# CortexM33 register map
Extracted from https://github.com/rp-rs/rp235x-pac/blob/main/svd/RP2350.svd.patched
CPU: CM33 r1p0, little endian, MPU, FPU, DSP, VTOR, 4 interrupt priority bits, 52 interrupts, 8 SAU regions
Registers are read-write, reset 0x0 unless marked. A register's access mark holds for its fields unless they carry their own. Offsets are from the block's base; lines under a group give offsets from that group; [hi:lo] are bit positions; {n}, {i} and the like mark numbered series; 'fields as' and 'values as' point back to an identical list; <NAME> marks a mode.

## Memory map
0xE0000000 PPB size 0x43000 — TEAL registers accessible through the debug interface
0xE0080000 EPPB size 0xC — Cortex-M33 EPPB vendor register block for RP2350

## EPPB — Cortex-M33 EPPB vendor register block for RP2350
Base 0xE0080000
0x00 NMI_MASK0 — NMI mask for IRQs 0 through 31. This register is core-local, and is reset by a processor warm reset.
  [31:0] NMI_MASK0
0x04 NMI_MASK1 — NMI mask for IRQs 0 though 51. This register is core-local, and is reset by a processor warm reset.
  [19:0] NMI_MASK1
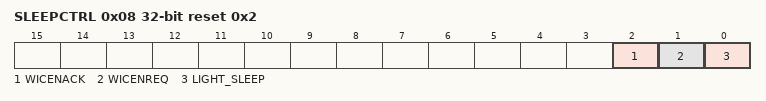
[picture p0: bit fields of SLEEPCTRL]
0x08 SLEEPCTRL access per field reset 0x2 — Nonstandard sleep control register
  [2] WICENACK ro — Status signal from the processor's interrupt controller. Changes to WICENREQ are eventually reflected in WICENACK.
  [1] WICENREQ rw — Request that the next processor deep sleep is a WIC sleep. After setting this bit, before sleeping, poll WICENACK to ensure the processor interrupt controller has acknowledged the change.
  [0] LIGHT_SLEEP rw — By default, any processor sleep will deassert the system-level clock request. Reenabling the clocks incurs 5 cycles of additional latency on wakeup. Setting LIGHT_SLEEP to 1 keeps the clock request asserted during a normal sleep (Arm SCR.SLEEPDEEP = 0), for faster wakeup. Processor deep sleep (Arm SCR.SLEEPDEEP = 1) is not affected, and will always deassert the system-level clock request.

## PPB (part 1 of 2) — TEAL registers accessible through the debug interface
Base 0xE0000000
{0x0+4i} ITM_STIM{i} (i=0..31) — Provides the interface for generating Instrumentation packets
  [31:0] STIMULUS — Data to write to the Stimulus Port FIFO, for forwarding as an Instrumentation packet. The size of write access determines the type of Instrumentation packet generated.
0xE00 ITM_TER0 — Provide an individual enable bit for each ITM_STIM register
  [31:0] STIMENA — For STIMENA[m] in ITM_TER*n, controls whether ITM_STIM(32*n + m) is enabled
0xE40 ITM_TPR — Controls which stimulus ports can be accessed by unprivileged code
  [3:0] PRIVMASK — Bit mask to enable tracing on ITM stimulus ports
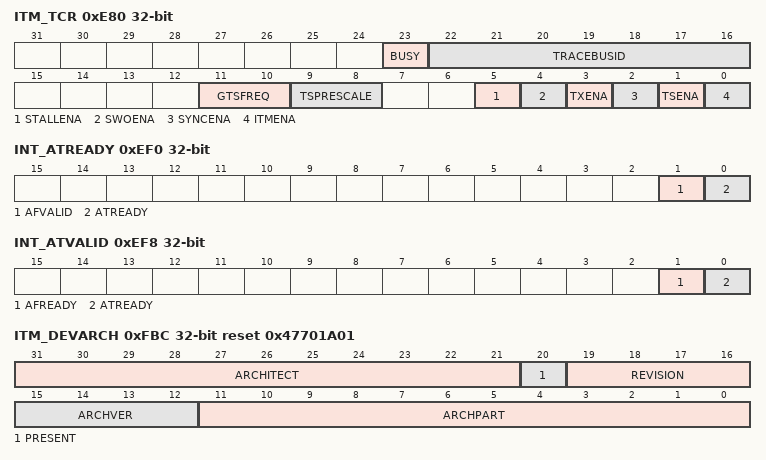
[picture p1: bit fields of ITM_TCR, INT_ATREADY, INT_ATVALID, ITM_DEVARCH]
0xE80 ITM_TCR access per field — Configures and controls transfers through the ITM interface
  [23] BUSY ro — Indicates whether the ITM is currently processing events
  [22:16] TRACEBUSID rw — Identifier for multi-source trace stream formatting. If multi-source trace is in use, the debugger must write a unique non-zero trace ID value to this field
  [11:10] GTSFREQ rw — Defines how often the ITM generates a global timestamp, based on the global timestamp clock frequency, or disables generation of global timestamps
  [9:8] TSPRESCALE rw — Local timestamp prescaler, used with the trace packet reference clock
  [5] STALLENA rw — Stall the PE to guarantee delivery of Data Trace packets.
  [4] SWOENA rw — Enables asynchronous clocking of the timestamp counter
  [3] TXENA rw — Enables forwarding of hardware event packet from the DWT unit to the ITM for output to the TPIU
  [2] SYNCENA rw — Enables Synchronization packet transmission for a synchronous TPIU
  [1] TSENA rw — Enables Local timestamp generation
  [0] ITMENA rw — Enables the ITM
0xEF0 INT_ATREADY ro — Integration Mode: Read ATB Ready
  [1] AFVALID — A read of this bit returns the value of AFVALID
  [0] ATREADY — A read of this bit returns the value of ATREADY
0xEF8 INT_ATVALID — Integration Mode: Write ATB Valid
  [1] AFREADY — A write to this bit gives the value of AFREADY
  [0] ATREADY — A write to this bit gives the value of ATVALID
0xF00 ITM_ITCTRL — Integration Mode Control Register
  [0] IME — Integration mode enable bit - The possible values are: 0 - The trace unit is not in integration mode. 1 - The trace unit is in integration mode. This mode enables: A debug agent to perform topology detection. SoC test software to perform integration testing.
0xFBC ITM_DEVARCH ro reset 0x47701A01 — Provides CoreSight discovery information for the ITM
  [31:21] ARCHITECT — Defines the architect of the component. Bits [31:28] are the JEP106 continuation code (JEP106 bank ID, minus 1) and bits [27:21] are the JEP106 ID code.
  [20] PRESENT — Defines that the DEVARCH register is present
  [19:16] REVISION — Defines the architecture revision of the component
  [15:12] ARCHVER — Defines the architecture version of the component
  [11:0] ARCHPART — Defines the architecture of the component
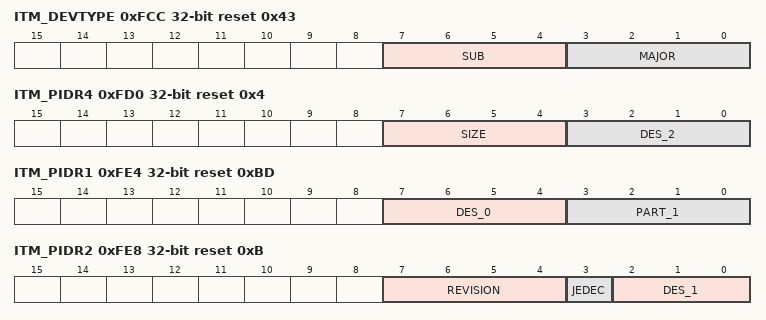
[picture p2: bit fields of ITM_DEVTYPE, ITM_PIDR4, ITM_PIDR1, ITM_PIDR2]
0xFCC ITM_DEVTYPE ro reset 0x43 — Provides CoreSight discovery information for the ITM
  [7:4] SUB — Component sub-type
  [3:0] MAJOR — Component major type
0xFD0 ITM_PIDR4 ro reset 0x4 — Provides CoreSight discovery information for the ITM
  [7:4] SIZE — See CoreSight Architecture Specification
  [3:0] DES_2 — See CoreSight Architecture Specification
{0xFC0+4i} ITM_PIDR{i} (i=5..7) — Provides CoreSight discovery information for the ITM
  [31:0] ITM_PIDR{i}
0xFE0 ITM_PIDR0 ro reset 0x21 — Provides CoreSight discovery information for the ITM
  [7:0] PART_0 — See CoreSight Architecture Specification
0xFE4 ITM_PIDR1 ro reset 0xBD — Provides CoreSight discovery information for the ITM
  [7:4] DES_0 — See CoreSight Architecture Specification
  [3:0] PART_1 — See CoreSight Architecture Specification
0xFE8 ITM_PIDR2 ro reset 0xB — Provides CoreSight discovery information for the ITM
  [7:4] REVISION — See CoreSight Architecture Specification
  [3] JEDEC — See CoreSight Architecture Specification
  [2:0] DES_1 — See CoreSight Architecture Specification
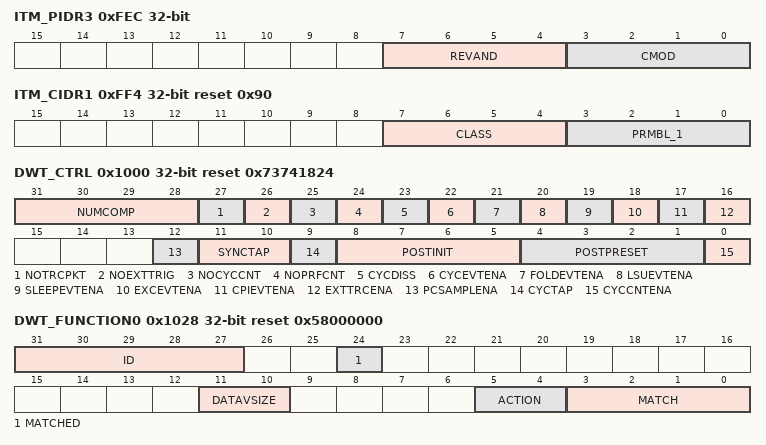
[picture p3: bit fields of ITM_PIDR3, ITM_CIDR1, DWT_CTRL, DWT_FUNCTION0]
0xFEC ITM_PIDR3 ro — Provides CoreSight discovery information for the ITM
  [7:4] REVAND — See CoreSight Architecture Specification
  [3:0] CMOD — See CoreSight Architecture Specification
0xFF0 ITM_CIDR0 ro reset 0xD — Provides CoreSight discovery information for the ITM
  [7:0] PRMBL_0 — See CoreSight Architecture Specification
0xFF4 ITM_CIDR1 ro reset 0x90 — Provides CoreSight discovery information for the ITM
  [7:4] CLASS — See CoreSight Architecture Specification
  [3:0] PRMBL_1 — See CoreSight Architecture Specification
0xFF8 ITM_CIDR2 ro reset 0x5 — Provides CoreSight discovery information for the ITM
  [7:0] PRMBL_2 — See CoreSight Architecture Specification
0xFFC ITM_CIDR3 ro reset 0xB1 — Provides CoreSight discovery information for the ITM
  [7:0] PRMBL_3 — See CoreSight Architecture Specification
0x1000 DWT_CTRL access per field reset 0x73741824 — Provides configuration and status information for the DWT unit, and used to control features of the unit
  [31:28] NUMCOMP ro — Number of DWT comparators implemented
  [27] NOTRCPKT ro — Indicates whether the implementation does not support trace
  [26] NOEXTTRIG ro — Reserved, RAZ
  [25] NOCYCCNT ro — Indicates whether the implementation does not include a cycle counter
  [24] NOPRFCNT ro — Indicates whether the implementation does not include the profiling counters
  [23] CYCDISS rw — Controls whether the cycle counter is disabled in Secure state
  [22] CYCEVTENA rw — Enables Event Counter packet generation on POSTCNT underflow
  [21] FOLDEVTENA rw — Enables DWT_FOLDCNT counter
  [20] LSUEVTENA rw — Enables DWT_LSUCNT counter
  [19] SLEEPEVTENA rw — Enable DWT_SLEEPCNT counter
  [18] EXCEVTENA rw — Enables DWT_EXCCNT counter
  [17] CPIEVTENA rw — Enables DWT_CPICNT counter
  [16] EXTTRCENA rw — Enables generation of Exception Trace packets
  [12] PCSAMPLENA rw — Enables use of POSTCNT counter as a timer for Periodic PC Sample packet generation
  [11:10] SYNCTAP rw — Selects the position of the synchronization packet counter tap on the CYCCNT counter. This determines the Synchronization packet rate
  [9] CYCTAP rw — Selects the position of the POSTCNT tap on the CYCCNT counter
  [8:5] POSTINIT rw — Initial value for the POSTCNT counter
  [4:1] POSTPRESET rw — Reload value for the POSTCNT counter
  [0] CYCCNTENA rw — Enables CYCCNT
0x1004 DWT_CYCCNT — Shows or sets the value of the processor cycle counter, CYCCNT
  [31:0] CYCCNT — Increments one on each processor clock cycle when DWT_CTRL.CYCCNTENA == 1 and DEMCR.TRCENA == 1. On overflow, CYCCNT wraps to zero
0x100C DWT_EXCCNT — Counts the total cycles spent in exception processing
  [7:0] EXCCNT — Counts one on each cycle when all of the following are true: - DWT_CTRL.EXCEVTENA == 1 and DEMCR.TRCENA == 1. - No instruction is executed, see DWT_CPICNT. - An exception-entry or exception-exit related operation is in progress. - Either SecureNoninvasiveDebugAllowed() == TRUE, or NS-Req for the operation is set to Non-secure and NoninvasiveDebugAllowed() == TRUE.
0x1014 DWT_LSUCNT — Increments on the additional cycles required to execute all load or store instructions
  [7:0] LSUCNT — Counts one on each cycle when all of the following are true: - DWT_CTRL.LSUEVTENA == 1 and DEMCR.TRCENA == 1. - No instruction is executed, see DWT_CPICNT. - No exception-entry or exception-exit operation is in progress, see DWT_EXCCNT. - A load-store operation is in progress. - Either SecureNoninvasiveDebugAllowed() == TRUE, or NS-Req for the operation is set to Non-secure and NoninvasiveDebugAllowed() == TRUE.
0x1018 DWT_FOLDCNT — Increments on the additional cycles required to execute all load or store instructions
  [7:0] FOLDCNT — Counts on each cycle when all of the following are true: - DWT_CTRL.FOLDEVTENA == 1 and DEMCR.TRCENA == 1. - At least two instructions are executed, see DWT_CPICNT. - Either SecureNoninvasiveDebugAllowed() == TRUE, or the PE is in Non-secure state and NoninvasiveDebugAllowed() == TRUE. The counter is incremented by the number of instructions executed, minus one
{0x1020+0x10*i} DWT_COMP{i} (i=0..3) — Provides a reference value for use by watchpoint comparator {i}
  [31:0] DWT_COMP{i}
0x1028 DWT_FUNCTION0 access per field reset 0x58000000 — Controls the operation of watchpoint comparator 0
  [31:27] ID ro — Identifies the capabilities for MATCH for comparator *n
  [24] MATCHED ro — Set to 1 when the comparator matches
  [11:10] DATAVSIZE rw — Defines the size of the object being watched for by Data Value and Data Address comparators
  [5:4] ACTION rw — Defines the action on a match. This field is ignored and the comparator generates no actions if it is disabled by MATCH
  [3:0] MATCH rw — Controls the type of match generated by this comparator
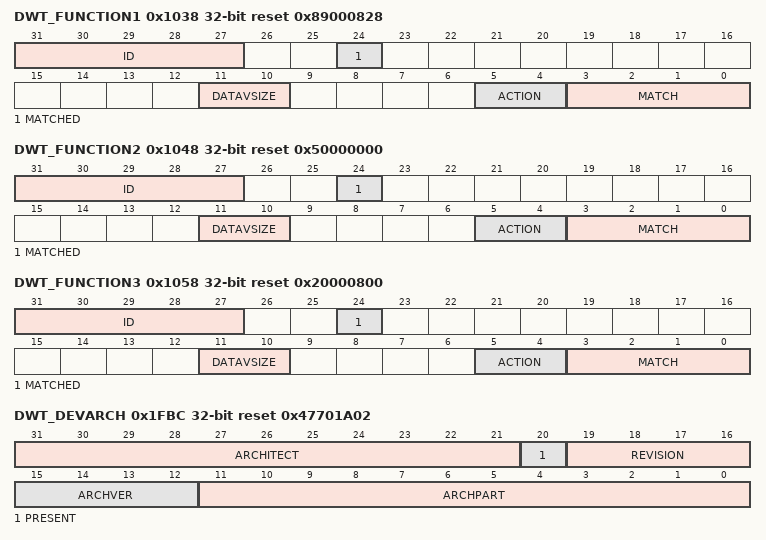
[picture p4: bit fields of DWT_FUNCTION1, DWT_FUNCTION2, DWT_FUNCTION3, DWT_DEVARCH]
0x1038 DWT_FUNCTION1 access per field reset 0x89000828 — Controls the operation of watchpoint comparator 1
  fields as DWT_FUNCTION0
0x1048 DWT_FUNCTION2 access per field reset 0x50000000 — Controls the operation of watchpoint comparator 2
  fields as DWT_FUNCTION0
0x1058 DWT_FUNCTION3 access per field reset 0x20000800 — Controls the operation of watchpoint comparator 3
  fields as DWT_FUNCTION0
0x1FBC DWT_DEVARCH ro reset 0x47701A02 — Provides CoreSight discovery information for the DWT
  fields as ITM_DEVARCH
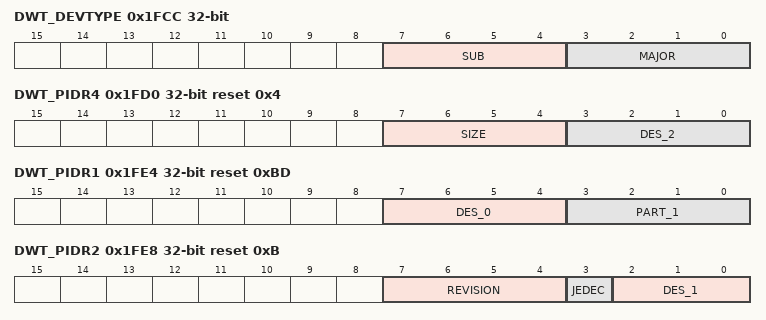
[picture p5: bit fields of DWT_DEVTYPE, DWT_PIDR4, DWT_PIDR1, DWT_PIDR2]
0x1FCC DWT_DEVTYPE ro — Provides CoreSight discovery information for the DWT
  [7:4] SUB — Component sub-type
  [3:0] MAJOR — Component major type
0x1FD0 DWT_PIDR4 ro reset 0x4 — Provides CoreSight discovery information for the DWT
  fields as ITM_PIDR4
{0x1FC0+4i} DWT_PIDR{i} (i=5..7) — Provides CoreSight discovery information for the DWT
  [31:0] DWT_PIDR{i}
0x1FE0 DWT_PIDR0 ro reset 0x21 — Provides CoreSight discovery information for the DWT
  [7:0] PART_0 — See CoreSight Architecture Specification
0x1FE4 DWT_PIDR1 ro reset 0xBD — Provides CoreSight discovery information for the DWT
  fields as ITM_PIDR1
0x1FE8 DWT_PIDR2 ro reset 0xB — Provides CoreSight discovery information for the DWT
  fields as ITM_PIDR2
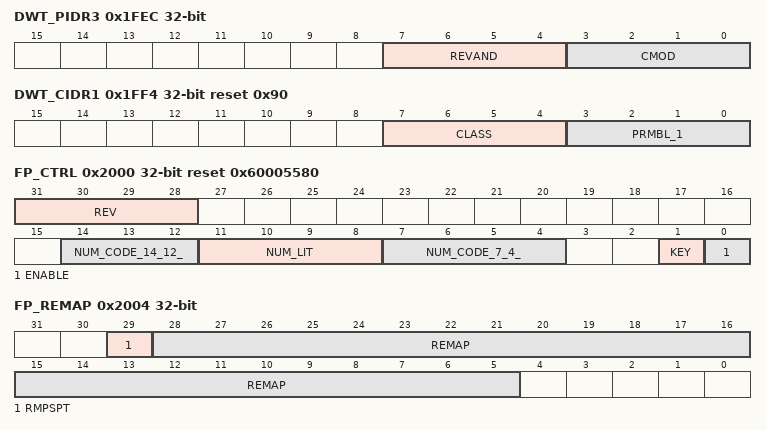
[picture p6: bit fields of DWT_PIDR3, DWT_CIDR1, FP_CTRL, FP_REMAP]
0x1FEC DWT_PIDR3 ro — Provides CoreSight discovery information for the DWT
  fields as ITM_PIDR3
0x1FF0 DWT_CIDR0 ro reset 0xD — Provides CoreSight discovery information for the DWT
  [7:0] PRMBL_0 — See CoreSight Architecture Specification
0x1FF4 DWT_CIDR1 ro reset 0x90 — Provides CoreSight discovery information for the DWT
  fields as ITM_CIDR1
0x1FF8 DWT_CIDR2 ro reset 0x5 — Provides CoreSight discovery information for the DWT
  [7:0] PRMBL_2 — See CoreSight Architecture Specification
0x1FFC DWT_CIDR3 ro reset 0xB1 — Provides CoreSight discovery information for the DWT
  [7:0] PRMBL_3 — See CoreSight Architecture Specification
0x2000 FP_CTRL access per field reset 0x60005580 — Provides FPB implementation information, and the global enable for the FPB unit
  [31:28] REV ro — Flash Patch and Breakpoint Unit architecture revision
  [14:12] NUM_CODE_14_12_ ro — Indicates the number of implemented instruction address comparators. Zero indicates no Instruction Address comparators are implemented. The Instruction Address comparators are numbered from 0 to NUM_CODE - 1
  [11:8] NUM_LIT ro — Indicates the number of implemented literal address comparators. The Literal Address comparators are numbered from NUM_CODE to NUM_CODE + NUM_LIT - 1
  [7:4] NUM_CODE_7_4_ ro — Indicates the number of implemented instruction address comparators. Zero indicates no Instruction Address comparators are implemented. The Instruction Address comparators are numbered from 0 to NUM_CODE - 1
  [1] KEY rw — Writes to the FP_CTRL are ignored unless KEY is concurrently written to one
  [0] ENABLE rw — Enables the FPB
0x2004 FP_REMAP ro — Indicates whether the implementation supports Flash Patch remap and, if it does, holds the target address for remap
  [29] RMPSPT — Indicates whether the FPB unit supports the Flash Patch remap function
  [28:5] REMAP — Holds the bits[28:5] of the Flash Patch remap address
{0x2008+4i} FP_COMP{i} (i=0..7) — Holds an address for comparison. The effect of the match depends on the configuration of the FPB and whether the comparator is an instruction address comparator or a literal address comparator
  [0] BE — Selects between flashpatch and breakpoint functionality
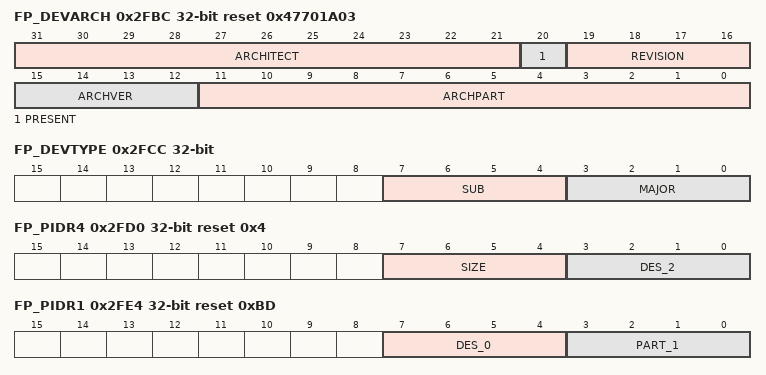
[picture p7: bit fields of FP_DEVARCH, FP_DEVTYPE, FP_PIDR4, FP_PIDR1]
0x2FBC FP_DEVARCH ro reset 0x47701A03 — Provides CoreSight discovery information for the FPB
  fields as ITM_DEVARCH
0x2FCC FP_DEVTYPE ro — Provides CoreSight discovery information for the FPB
  [7:4] SUB — Component sub-type
  [3:0] MAJOR — Component major type
0x2FD0 FP_PIDR4 ro reset 0x4 — Provides CoreSight discovery information for the FP
  fields as ITM_PIDR4
{0x2FC0+4i} FP_PIDR{i} (i=5..7) — Provides CoreSight discovery information for the FP
  [31:0] FP_PIDR{i}
0x2FE0 FP_PIDR0 ro reset 0x21 — Provides CoreSight discovery information for the FP
  [7:0] PART_0 — See CoreSight Architecture Specification
0x2FE4 FP_PIDR1 ro reset 0xBD — Provides CoreSight discovery information for the FP
  fields as ITM_PIDR1
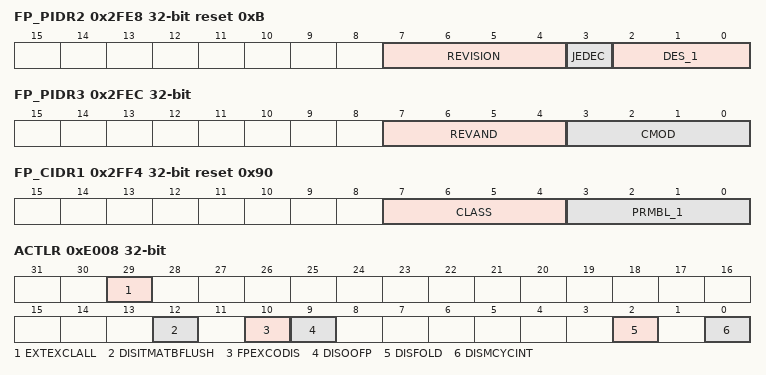
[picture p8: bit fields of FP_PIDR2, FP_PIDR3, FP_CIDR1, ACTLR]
0x2FE8 FP_PIDR2 ro reset 0xB — Provides CoreSight discovery information for the FP
  fields as ITM_PIDR2
0x2FEC FP_PIDR3 ro — Provides CoreSight discovery information for the FP
  fields as ITM_PIDR3
0x2FF0 FP_CIDR0 ro reset 0xD — Provides CoreSight discovery information for the FP
  [7:0] PRMBL_0 — See CoreSight Architecture Specification
0x2FF4 FP_CIDR1 ro reset 0x90 — Provides CoreSight discovery information for the FP
  fields as ITM_CIDR1
0x2FF8 FP_CIDR2 ro reset 0x5 — Provides CoreSight discovery information for the FP
  [7:0] PRMBL_2 — See CoreSight Architecture Specification
0x2FFC FP_CIDR3 ro reset 0xB1 — Provides CoreSight discovery information for the FP
  [7:0] PRMBL_3 — See CoreSight Architecture Specification
0xE004 ICTR ro reset 0x1 — Provides information about the interrupt controller
  [3:0] INTLINESNUM — Indicates the number of the highest implemented register in each of the NVIC control register sets, or in the case of NVIC_IPR*n, 4×INTLINESNUM
0xE008 ACTLR — Provides IMPLEMENTATION DEFINED configuration and control options
  [29] EXTEXCLALL — External Exclusives Allowed with no MPU
  [12] DISITMATBFLUSH — Disable ATB Flush
  [10] FPEXCODIS — Disable FPU exception outputs
  [9] DISOOFP — Disable out-of-order FP instruction completion
  [2] DISFOLD — Disable dual-issue.
  [0] DISMCYCINT — Disable dual-issue.
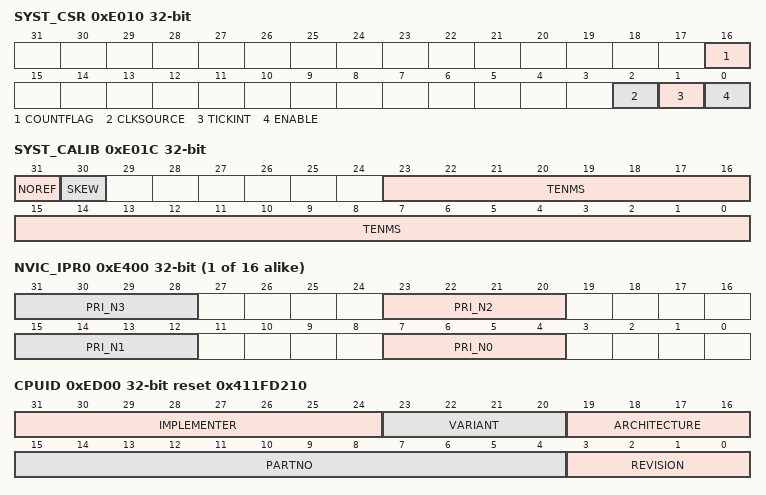
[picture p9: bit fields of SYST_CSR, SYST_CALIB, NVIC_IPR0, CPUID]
0xE010 SYST_CSR access per field — Use the SysTick Control and Status Register to enable the SysTick features.
  [16] COUNTFLAG ro — Returns 1 if timer counted to 0 since last time this was read. Clears on read by application or debugger.
  [2] CLKSOURCE rw — SysTick clock source. Always reads as one if SYST_CALIB reports NOREF. Selects the SysTick timer clock source: 0 = External reference clock. 1 = Processor clock.
  [1] TICKINT rw — Enables SysTick exception request: 0 = Counting down to zero does not assert the SysTick exception request. 1 = Counting down to zero to asserts the SysTick exception request.
  [0] ENABLE rw — Enable SysTick counter: 0 = Counter disabled. 1 = Counter enabled.
0xE014 SYST_RVR — Use the SysTick Reload Value Register to specify the start value to load into the current value register when the counter reaches 0. It can be any value between 0 and 0x00FFFFFF. A start value of 0 is possible, but has no effect because the SysTick interrupt and COUNTFLAG are activated when counting from 1 to 0. The reset value of this register is UNKNOWN. To generate a multi-shot timer with a period of N processor clock cycles, use a RELOAD value of N-1. For example, if the SysTick interrupt is required every 100 clock pulses, set RELOAD to 99.
  [23:0] RELOAD — Value to load into the SysTick Current Value Register when the counter reaches 0.
0xE018 SYST_CVR — Use the SysTick Current Value Register to find the current value in the register. The reset value of this register is UNKNOWN.
  [23:0] CURRENT — Reads return the current value of the SysTick counter. This register is write-clear. Writing to it with any value clears the register to 0. Clearing this register also clears the COUNTFLAG bit of the SysTick Control and Status Register.
0xE01C SYST_CALIB ro — Use the SysTick Calibration Value Register to enable software to scale to any required speed using divide and multiply.
  [31] NOREF — If reads as 1, the Reference clock is not provided - the CLKSOURCE bit of the SysTick Control and Status register will be forced to 1 and cannot be cleared to 0.
  [30] SKEW — If reads as 1, the calibration value for 10ms is inexact (due to clock frequency).
  [23:0] TENMS — An optional Reload value to be used for 10ms (100Hz) timing, subject to system clock skew errors. If the value reads as 0, the calibration value is not known.
0xE100 NVIC_ISER0 — Enables or reads the enabled state of each group of 32 interrupts
  [31:0] SETENA — For SETENA[m] in NVIC_ISER*n, indicates whether interrupt 32*n + m is enabled
0xE104 NVIC_ISER1 — Enables or reads the enabled state of each group of 32 interrupts
  fields as NVIC_ISER0
0xE180 NVIC_ICER0 — Clears or reads the enabled state of each group of 32 interrupts
  [31:0] CLRENA — For CLRENA[m] in NVIC_ICER*n, indicates whether interrupt 32*n + m is enabled
0xE184 NVIC_ICER1 — Clears or reads the enabled state of each group of 32 interrupts
  fields as NVIC_ICER0
0xE200 NVIC_ISPR0 — Enables or reads the pending state of each group of 32 interrupts
  [31:0] SETPEND — For SETPEND[m] in NVIC_ISPR*n, indicates whether interrupt 32*n + m is pending
0xE204 NVIC_ISPR1 — Enables or reads the pending state of each group of 32 interrupts
  fields as NVIC_ISPR0
0xE280 NVIC_ICPR0 — Clears or reads the pending state of each group of 32 interrupts
  [31:0] CLRPEND — For CLRPEND[m] in NVIC_ICPR*n, indicates whether interrupt 32*n + m is pending
0xE284 NVIC_ICPR1 — Clears or reads the pending state of each group of 32 interrupts
  fields as NVIC_ICPR0
0xE300 NVIC_IABR0 — For each group of 32 interrupts, shows the active state of each interrupt
  [31:0] ACTIVE — For ACTIVE[m] in NVIC_IABR*n, indicates the active state for interrupt 32*n+m
0xE304 NVIC_IABR1 — For each group of 32 interrupts, shows the active state of each interrupt
  fields as NVIC_IABR0
0xE380 NVIC_ITNS0 — For each group of 32 interrupts, determines whether each interrupt targets Non-secure or Secure state
  [31:0] ITNS — For ITNS[m] in NVIC_ITNS*n, `IAAMO the target Security state for interrupt 32*n+m
0xE384 NVIC_ITNS1 — For each group of 32 interrupts, determines whether each interrupt targets Non-secure or Secure state
  fields as NVIC_ITNS0
{0xE400+4i} NVIC_IPR{i} (i=0..15) — Sets or reads interrupt priorities
  [8n+7:8n+4] PRI_N{n} (n=0..3) — For register NVIC_IPRn, the priority of interrupt number 4*n+{n}, or RES0 if the PE does not implement this interrupt
0xED00 CPUID ro reset 0x411FD210 — Provides identification information for the PE, including an implementer code for the device and a device ID number
  [31:24] IMPLEMENTER — This field must hold an implementer code that has been assigned by ARM
  [23:20] VARIANT — IMPLEMENTATION DEFINED variant number. Typically, this field is used to distinguish between different product variants, or major revisions of a product
  [19:16] ARCHITECTURE — Defines the Architecture implemented by the PE
  [15:4] PARTNO — IMPLEMENTATION DEFINED primary part number for the device
  [3:0] REVISION — IMPLEMENTATION DEFINED revision number for the device
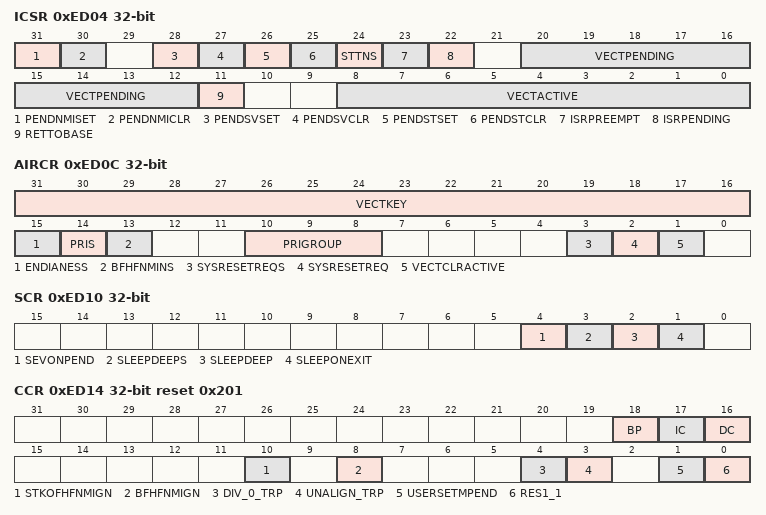
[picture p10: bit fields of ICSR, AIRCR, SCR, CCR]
0xED04 ICSR access per field — Controls and provides status information for NMI, PendSV, SysTick and interrupts
  [31] PENDNMISET ro — Indicates whether the NMI exception is pending
  [30] PENDNMICLR rw — Allows the NMI exception pend state to be cleared
  [28] PENDSVSET ro — Indicates whether the PendSV `FTSSS exception is pending
  [27] PENDSVCLR rw — Allows the PendSV exception pend state to be cleared `FTSSS
  [26] PENDSTSET ro — Indicates whether the SysTick `FTSSS exception is pending
  [25] PENDSTCLR rw — Allows the SysTick exception pend state to be cleared `FTSSS
  [24] STTNS rw — Controls whether in a single SysTick implementation, the SysTick is Secure or Non-secure
  [23] ISRPREEMPT ro — Indicates whether a pending exception will be serviced on exit from debug halt state
  [22] ISRPENDING ro — Indicates whether an external interrupt, generated by the NVIC, is pending
  [20:12] VECTPENDING ro — The exception number of the highest priority pending and enabled interrupt
  [11] RETTOBASE ro — In Handler mode, indicates whether there is more than one active exception
  [8:0] VECTACTIVE ro — The exception number of the current executing exception
0xED08 VTOR — The VTOR indicates the offset of the vector table base address from memory address 0x00000000.
  [31:7] TBLOFF — Vector table base offset field. It contains bits[31:7] of the offset of the table base from the bottom of the memory map.
0xED0C AIRCR access per field — Use the Application Interrupt and Reset Control Register to: determine data endianness, clear all active state information from debug halt mode, request a system reset.
  [31:16] VECTKEY rw — Register key: Reads as Unknown On writes, write 0x05FA to VECTKEY, otherwise the write is ignored.
  [15] ENDIANESS ro — Data endianness implemented: 0 = Little-endian.
  [14] PRIS rw — Prioritize Secure exceptions. The value of this bit defines whether Secure exception priority boosting is enabled. 0 Priority ranges of Secure and Non-secure exceptions are identical. 1 Non-secure exceptions are de-prioritized.
  [13] BFHFNMINS rw — BusFault, HardFault, and NMI Non-secure enable. 0 BusFault, HardFault, and NMI are Secure. 1 BusFault and NMI are Non-secure and exceptions can target Non-secure HardFault.
  [10:8] PRIGROUP rw — Interrupt priority grouping field. This field determines the split of group priority from subpriority. See https://developer.arm.com/documentation/100235/0004/the-cortex-m33-peripherals/system-control-block/application-interrupt-and-reset-control-register?lang=en
  [3] SYSRESETREQS rw — System reset request, Secure state only. 0 SYSRESETREQ functionality is available to both Security states. 1 SYSRESETREQ functionality is only available to Secure state.
  [2] SYSRESETREQ rw — Writing 1 to this bit causes the SYSRESETREQ signal to the outer system to be asserted to request a reset. The intention is to force a large system reset of all major components except for debug. The C_HALT bit in the DHCSR is cleared as a result of the system reset requested. The debugger does not lose contact with the device.
  [1] VECTCLRACTIVE rw — Clears all active state information for fixed and configurable exceptions. This bit: is self-clearing, can only be set by the DAP when the core is halted. When set: clears all active exception status of the processor, forces a return to Thread mode, forces an IPSR of 0. A debugger must re-initialize the stack.
0xED10 SCR — System Control Register. Use the System Control Register for power-management functions: signal to the system when the processor can enter a low power state, control how the processor enters and exits low power states.
  [4] SEVONPEND — Send Event on Pending bit: 0 = Only enabled interrupts or events can wakeup the processor, disabled interrupts are excluded. 1 = Enabled events and all interrupts, including disabled interrupts, can wakeup the processor. When an event or interrupt becomes pending, the event signal wakes up the processor from WFE. If the processor is not waiting for an event, the event is registered and affects the next WFE. The processor also wakes up on execution of an SEV instruction or an external event.
  [3] SLEEPDEEPS — 0 SLEEPDEEP is available to both security states 1 SLEEPDEEP is only available to Secure state
  [2] SLEEPDEEP — Controls whether the processor uses sleep or deep sleep as its low power mode: 0 = Sleep. 1 = Deep sleep.
  [1] SLEEPONEXIT — Indicates sleep-on-exit when returning from Handler mode to Thread mode: 0 = Do not sleep when returning to Thread mode. 1 = Enter sleep, or deep sleep, on return from an ISR to Thread mode. Setting this bit to 1 enables an interrupt driven application to avoid returning to an empty main application.
0xED14 CCR access per field reset 0x201 — Sets or returns configuration and control data
  [18] BP ro — Enables program flow prediction `FTSSS
  [17] IC ro — This is a global enable bit for instruction caches in the selected Security state
  [16] DC ro — Enables data caching of all data accesses to Normal memory `FTSSS
  [10] STKOFHFNMIGN rw — Controls the effect of a stack limit violation while executing at a requested priority less than 0
  [8] BFHFNMIGN rw — Determines the effect of precise BusFaults on handlers running at a requested priority less than 0
  [4] DIV_0_TRP rw — Controls the generation of a DIVBYZERO UsageFault when attempting to perform integer division by zero
  [3] UNALIGN_TRP rw — Controls the trapping of unaligned word or halfword accesses
  [1] USERSETMPEND rw — Determines whether unprivileged accesses are permitted to pend interrupts via the STIR
  [0] RES1_1 ro — Reserved, RES1
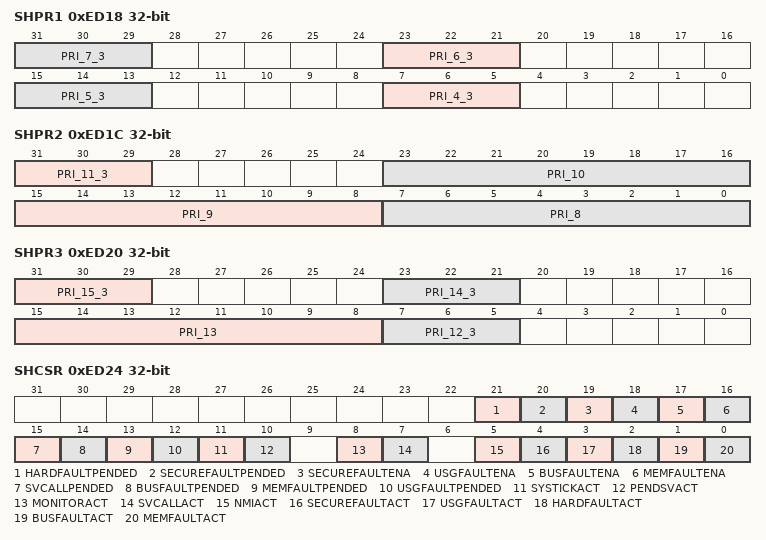
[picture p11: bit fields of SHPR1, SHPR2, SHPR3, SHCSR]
0xED18 SHPR1 — Sets or returns priority for system handlers 4 - 7
  [8n-25:8n-27] PRI_{n}_3 (n=4..7) — Priority of system handler {n}, SecureFault
0xED1C SHPR2 access per field — Sets or returns priority for system handlers 8 - 11
  [31:29] PRI_11_3 rw — Priority of system handler 11, SecureFault
  [23:16] PRI_10 ro — Reserved, RES0
  [15:8] PRI_9 ro — Reserved, RES0
  [7:0] PRI_8 ro — Reserved, RES0
0xED20 SHPR3 access per field — Sets or returns priority for system handlers 12 - 15
  [31:29] PRI_15_3 rw — Priority of system handler 15, SecureFault
  [23:21] PRI_14_3 rw — Priority of system handler 14, SecureFault
  [15:8] PRI_13 ro — Reserved, RES0
  [7:5] PRI_12_3 rw — Priority of system handler 12, SecureFault
0xED24 SHCSR — Provides access to the active and pending status of system exceptions
  [21] HARDFAULTPENDED — `IAAMO the pending state of the HardFault exception `CTTSSS
  [20] SECUREFAULTPENDED — `IAAMO the pending state of the SecureFault exception
  [19] SECUREFAULTENA — `DW the SecureFault exception is enabled
  [18] USGFAULTENA — `DW the UsageFault exception is enabled `FTSSS
  [17] BUSFAULTENA — `DW the BusFault exception is enabled
  [16] MEMFAULTENA — `DW the MemManage exception is enabled `FTSSS
  [15] SVCALLPENDED — `IAAMO the pending state of the SVCall exception `FTSSS
  [14] BUSFAULTPENDED — `IAAMO the pending state of the BusFault exception
  [13] MEMFAULTPENDED — `IAAMO the pending state of the MemManage exception `FTSSS
  [12] USGFAULTPENDED — The UsageFault exception is banked between Security states, `IAAMO the pending state of the UsageFault exception `FTSSS
  [11] SYSTICKACT — `IAAMO the active state of the SysTick exception `FTSSS
  [10] PENDSVACT — `IAAMO the active state of the PendSV exception `FTSSS
  [8] MONITORACT — `IAAMO the active state of the DebugMonitor exception
  [7] SVCALLACT — `IAAMO the active state of the SVCall exception `FTSSS
  [5] NMIACT — `IAAMO the active state of the NMI exception
  [4] SECUREFAULTACT — `IAAMO the active state of the SecureFault exception
  [3] USGFAULTACT — `IAAMO the active state of the UsageFault exception `FTSSS
  [2] HARDFAULTACT — Indicates and allows limited modification of the active state of the HardFault exception `FTSSS
  [1] BUSFAULTACT — `IAAMO the active state of the BusFault exception
  [0] MEMFAULTACT — `IAAMO the active state of the MemManage exception `FTSSS
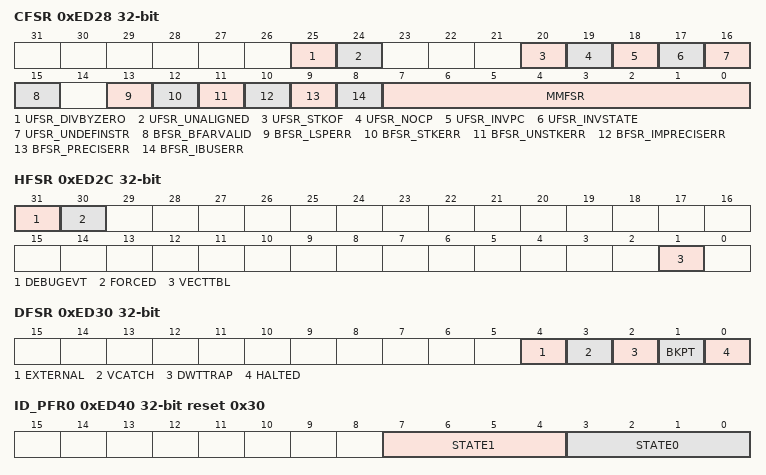
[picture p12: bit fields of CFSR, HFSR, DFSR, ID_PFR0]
0xED28 CFSR — Contains the three Configurable Fault Status Registers. 31:16 UFSR: Provides information on UsageFault exceptions 15:8 BFSR: Provides information on BusFault exceptions 7:0 MMFSR: Provides information on MemManage exceptions
  [25] UFSR_DIVBYZERO — Sticky flag indicating whether an integer division by zero error has occurred
  [24] UFSR_UNALIGNED — Sticky flag indicating whether an unaligned access error has occurred
  [20] UFSR_STKOF — Sticky flag indicating whether a stack overflow error has occurred
  [19] UFSR_NOCP — Sticky flag indicating whether a coprocessor disabled or not present error has occurred
  [18] UFSR_INVPC — Sticky flag indicating whether an integrity check error has occurred
  [17] UFSR_INVSTATE — Sticky flag indicating whether an EPSR.T or EPSR.IT validity error has occurred
  [16] UFSR_UNDEFINSTR — Sticky flag indicating whether an undefined instruction error has occurred
  [15] BFSR_BFARVALID — Indicates validity of the contents of the BFAR register
  [13] BFSR_LSPERR — Records whether a BusFault occurred during FP lazy state preservation
  [12] BFSR_STKERR — Records whether a derived BusFault occurred during exception entry stacking
  [11] BFSR_UNSTKERR — Records whether a derived BusFault occurred during exception return unstacking
  [10] BFSR_IMPRECISERR — Records whether an imprecise data access error has occurred
  [9] BFSR_PRECISERR — Records whether a precise data access error has occurred
  [8] BFSR_IBUSERR — Records whether a BusFault on an instruction prefetch has occurred
  [7:0] MMFSR — Provides information on MemManage exceptions
0xED2C HFSR — Shows the cause of any HardFaults
  [31] DEBUGEVT — Indicates when a Debug event has occurred
  [30] FORCED — Indicates that a fault with configurable priority has been escalated to a HardFault exception, because it could not be made active, because of priority, or because it was disabled
  [1] VECTTBL — Indicates when a fault has occurred because of a vector table read error on exception processing
0xED30 DFSR — Shows which debug event occurred
  [4] EXTERNAL — Sticky flag indicating whether an External debug request debug event has occurred
  [3] VCATCH — Sticky flag indicating whether a Vector catch debug event has occurred
  [2] DWTTRAP — Sticky flag indicating whether a Watchpoint debug event has occurred
  [1] BKPT — Sticky flag indicating whether a Breakpoint debug event has occurred
  [0] HALTED — Sticky flag indicating that a Halt request debug event or Step debug event has occurred
0xED34 MMFAR — Shows the address of the memory location that caused an MPU fault
  [31:0] ADDRESS — This register is updated with the address of a location that produced a MemManage fault. The MMFSR shows the cause of the fault, and whether this field is valid. This field is valid only when MMFSR.MMARVALID is set, otherwise it is UNKNOWN
0xED38 BFAR — Shows the address associated with a precise data access BusFault
  [31:0] ADDRESS — This register is updated with the address of a location that produced a BusFault. The BFSR shows the reason for the fault. This field is valid only when BFSR.BFARVALID is set, otherwise it is UNKNOWN
0xED40 ID_PFR0 ro reset 0x30 — Gives top-level information about the instruction set supported by the PE
  [7:4] STATE1 — T32 instruction set support
  [3:0] STATE0 — A32 instruction set support
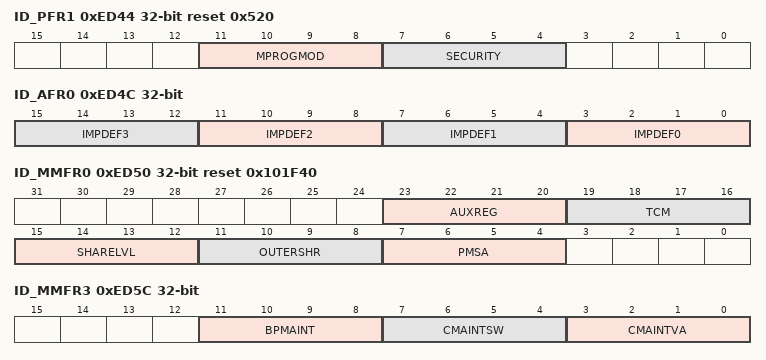
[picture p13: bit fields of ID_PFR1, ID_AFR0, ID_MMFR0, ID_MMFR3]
0xED44 ID_PFR1 ro reset 0x520 — Gives information about the programmers' model and Extensions support
  [11:8] MPROGMOD — Identifies support for the M-Profile programmers' model support
  [7:4] SECURITY — Identifies whether the Security Extension is implemented
0xED48 ID_DFR0 ro reset 0x200000 — Provides top level information about the debug system
  [23:20] MPROFDBG — Indicates the supported M-profile debug architecture
0xED4C ID_AFR0 ro — Provides information about the IMPLEMENTATION DEFINED features of the PE
  [4n+3:4n] IMPDEF{n} (n=0..3) — IMPLEMENTATION DEFINED meaning
0xED50 ID_MMFR0 ro reset 0x101F40 — Provides information about the implemented memory model and memory management support
  [23:20] AUXREG — Indicates support for Auxiliary Control Registers
  [19:16] TCM — Indicates support for tightly coupled memories (TCMs)
  [15:12] SHARELVL — Indicates the number of shareability levels implemented
  [11:8] OUTERSHR — Indicates the outermost shareability domain implemented
  [7:4] PMSA — Indicates support for the protected memory system architecture (PMSA)
0xED54 ID_MMFR1 — Provides information about the implemented memory model and memory management support
  [31:0] ID_MMFR1
0xED58 ID_MMFR2 ro reset 0x1000000 — Provides information about the implemented memory model and memory management support
  [27:24] WFISTALL — Indicates the support for Wait For Interrupt (WFI) stalling
0xED5C ID_MMFR3 ro — Provides information about the implemented memory model and memory management support
  [11:8] BPMAINT — Indicates the supported branch predictor maintenance
  [7:4] CMAINTSW — Indicates the supported cache maintenance operations by set/way
  [3:0] CMAINTVA — Indicates the supported cache maintenance operations by address
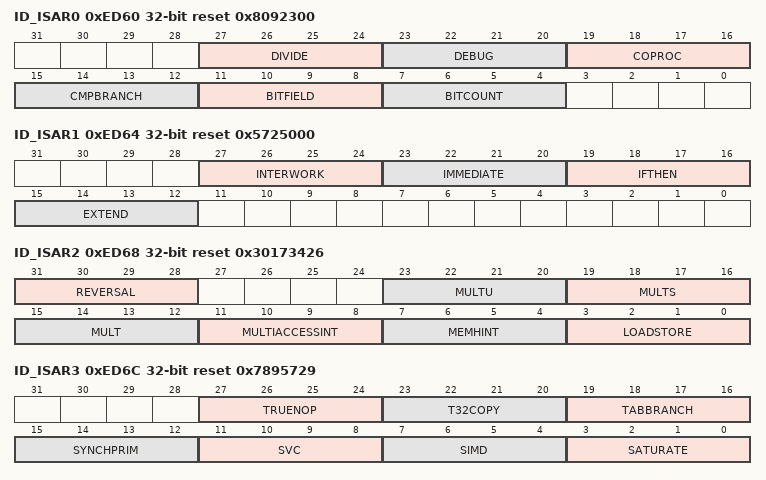
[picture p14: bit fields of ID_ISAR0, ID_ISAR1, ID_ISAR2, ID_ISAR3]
0xED60 ID_ISAR0 ro reset 0x8092300 — Provides information about the instruction set implemented by the PE
  [27:24] DIVIDE — Indicates the supported Divide instructions
  [23:20] DEBUG — Indicates the implemented Debug instructions
  [19:16] COPROC — Indicates the supported Coprocessor instructions
  [15:12] CMPBRANCH — Indicates the supported combined Compare and Branch instructions
  [11:8] BITFIELD — Indicates the supported bit field instructions
  [7:4] BITCOUNT — Indicates the supported bit count instructions
0xED64 ID_ISAR1 ro reset 0x5725000 — Provides information about the instruction set implemented by the PE
  [27:24] INTERWORK — Indicates the implemented Interworking instructions
  [23:20] IMMEDIATE — Indicates the implemented for data-processing instructions with long immediates
  [19:16] IFTHEN — Indicates the implemented If-Then instructions
  [15:12] EXTEND — Indicates the implemented Extend instructions
0xED68 ID_ISAR2 ro reset 0x30173426 — Provides information about the instruction set implemented by the PE
  [31:28] REVERSAL — Indicates the implemented Reversal instructions
  [23:20] MULTU — Indicates the implemented advanced unsigned Multiply instructions
  [19:16] MULTS — Indicates the implemented advanced signed Multiply instructions
  [15:12] MULT — Indicates the implemented additional Multiply instructions
  [11:8] MULTIACCESSINT — Indicates the support for interruptible multi-access instructions
  [7:4] MEMHINT — Indicates the implemented Memory Hint instructions
  [3:0] LOADSTORE — Indicates the implemented additional load/store instructions
0xED6C ID_ISAR3 ro reset 0x7895729 — Provides information about the instruction set implemented by the PE
  [27:24] TRUENOP — Indicates the implemented true NOP instructions
  [23:20] T32COPY — Indicates the support for T32 non flag-setting MOV instructions
  [19:16] TABBRANCH — Indicates the implemented Table Branch instructions
  [15:12] SYNCHPRIM — Used in conjunction with ID_ISAR4.SynchPrim_frac to indicate the implemented Synchronization Primitive instructions
  [11:8] SVC — Indicates the implemented SVC instructions
  [7:4] SIMD — Indicates the implemented SIMD instructions
  [3:0] SATURATE — Indicates the implemented saturating instructions
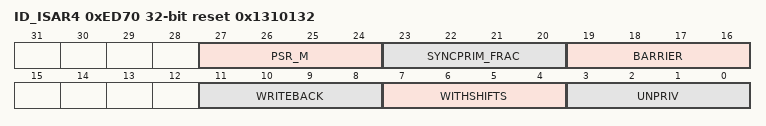
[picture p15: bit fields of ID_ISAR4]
0xED70 ID_ISAR4 ro reset 0x1310132 — Provides information about the instruction set implemented by the PE
  [27:24] PSR_M — Indicates the implemented M profile instructions to modify the PSRs
  [23:20] SYNCPRIM_FRAC — Used in conjunction with ID_ISAR3.SynchPrim to indicate the implemented Synchronization Primitive instructions
  [19:16] BARRIER — Indicates the implemented Barrier instructions
  [11:8] WRITEBACK — Indicates the support for writeback addressing modes
  [7:4] WITHSHIFTS — Indicates the support for writeback addressing modes
  [3:0] UNPRIV — Indicates the implemented unprivileged instructions
0xED74 ID_ISAR5 — Provides information about the instruction set implemented by the PE
  [31:0] ID_ISAR5
